VERSION ""

NS_ :

BS_:

BU_:

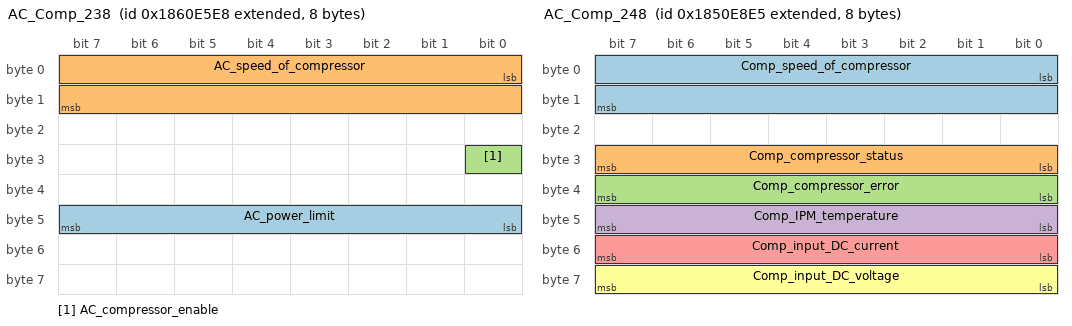
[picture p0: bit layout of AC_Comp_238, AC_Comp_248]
BO_ 2556487144 AC_Comp_238: 8 Vector__XXX
 SG_ AC_power_limit : 40|8@1+ (1,0) [0|255] "" Vector__XXX
 SG_ AC_speed_of_compressor : 0|16@1+ (1,0) [0|65534] "rpm" Vector__XXX
 SG_ AC_compressor_enable : 24|1@1+ (1,0) [0|1] "" Vector__XXX

BO_ 2555439333 AC_Comp_248: 8 Vector__XXX
 SG_ Comp_speed_of_compressor : 0|16@1+ (1,0) [0|65534] "rpm" Vector__XXX
 SG_ Comp_compressor_status : 24|8@1+ (1,0) [0|0] "" Vector__XXX
 SG_ Comp_compressor_error : 32|8@1+ (1,0) [0|254] "" Vector__XXX
 SG_ Comp_IPM_temperature : 40|8@1+ (1,0) [0|254] "" Vector__XXX
 SG_ Comp_input_DC_current : 48|8@1+ (0.1,0) [0|25.4] "" Vector__XXX
 SG_ Comp_input_DC_voltage : 56|8@1+ (4,0) [0|1016] "" Vector__XXX

CM_ BO_ 2556487144 "command from vehicle/system to compressor";
CM_ SG_ 2556487144 AC_speed_of_compressor "Target speed";
CM_ SG_ 2556487144 AC_compressor_enable "1=on 0=off";
CM_ BO_ 2555439333 "feedback from compressor";
CM_ SG_ 2555439333 Comp_speed_of_compressor "Actual speed feedback from compressor";
CM_ SG_ 2555439333 Comp_compressor_status "0=off
1=running
3=fault";
CM_ SG_ 2555439333 Comp_compressor_error "0x00:No Error
0x01:Over Current
0x02:Over Voltage 
0x04:Under Voltage
0x08:Standby over voltage
0x10:Standby under voltage
0x20:Communication Error
0x40:Over Current Lock
0x80:Over Power Lock";
CM_ SG_ 2555439333 Comp_IPM_temperature "Temperature sensor measured value";
CM_ SG_ 2555439333 Comp_input_DC_current "DC Current sensor measured value";
CM_ SG_ 2555439333 Comp_input_DC_voltage "DC Voltage sensor measured value";
